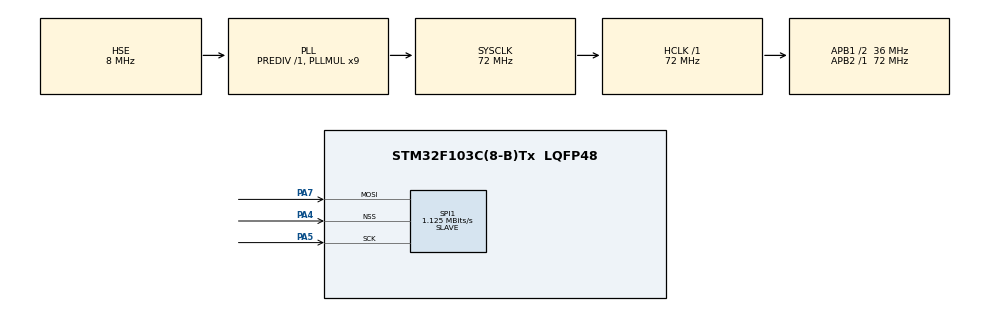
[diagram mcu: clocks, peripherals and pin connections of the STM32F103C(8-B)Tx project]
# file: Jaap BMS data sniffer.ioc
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Dma.Request0=SPI1_RX
Dma.SPI1_RX.0.Direction=DMA_PERIPH_TO_MEMORY
Dma.SPI1_RX.0.Instance=DMA1_Channel2
Dma.SPI1_RX.0.MemDataAlignment=DMA_MDATAALIGN_BYTE
Dma.SPI1_RX.0.MemInc=DMA_MINC_ENABLE
Dma.SPI1_RX.0.Mode=DMA_CIRCULAR
Dma.SPI1_RX.0.PeriphDataAlignment=DMA_PDATAALIGN_BYTE
Dma.SPI1_RX.0.PeriphInc=DMA_PINC_DISABLE
Dma.SPI1_RX.0.Priority=DMA_PRIORITY_LOW
Mcu.Family=STM32F1
Mcu.Name=STM32F103C(8-B)Tx
Mcu.Package=LQFP48
NVIC.PriorityGroup=NVIC_PRIORITYGROUP_4
PA13.Mode=Serial_Wire
PA13.Signal=SYS_JTMS-SWDIO
PA14.Mode=Serial_Wire
PA14.Signal=SYS_JTCK-SWCLK
PA4.Mode=NSS_Signal_Hard_Input
PA4.Signal=SPI1_NSS
PA5.Mode=RX_Only_Simplex_Unidirect_Slave
PA5.Signal=SPI1_SCK
PA7.Mode=RX_Only_Simplex_Unidirect_Slave
PA7.Signal=SPI1_MOSI
PD0-OSC_IN.Mode=HSE-External-Oscillator
PD0-OSC_IN.Signal=RCC_OSC_IN
PD1-OSC_OUT.Mode=HSE-External-Oscillator
PD1-OSC_OUT.Signal=RCC_OSC_OUT
ProjectManager.HeapSize=0x200
ProjectManager.StackSize=0x400
ProjectManager.TargetToolchain=STM32CubeIDE
RCC.AHBFreq_Value=72000000
RCC.APB1CLKDivider=RCC_HCLK_DIV2
RCC.APB1Freq_Value=36000000
RCC.APB1TimFreq_Value=72000000
RCC.APB2Freq_Value=72000000
RCC.APB2TimFreq_Value=72000000
RCC.HCLKFreq_Value=72000000
RCC.PLLMUL=RCC_PLL_MUL9
RCC.PLLSourceVirtual=RCC_PLLSOURCE_HSE
RCC.SYSCLKFreq_VALUE=72000000
RCC.SYSCLKSource=RCC_SYSCLKSOURCE_PLLCLK
RCC.USBFreq_Value=72000000
SPI1.BaudRatePrescaler=SPI_BAUDRATEPRESCALER_64
SPI1.CalculateBaudRate=1.125 MBits/s
SPI1.Direction=SPI_DIRECTION_2LINES_RXONLY
SPI1.Mode=SPI_MODE_SLAVE
SPI1.VirtualNSS=VM_NSSHARD
SPI1.VirtualType=VM_SLAVE
board=custom

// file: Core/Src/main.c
/* USER CODE BEGIN Header */
/**
 ******************************************************************************
 * @file           : main.c
 * @brief          : Main program body
 ******************************************************************************
 * @attention
 *
 * <h2><center>&copy; Copyright (c) 2021 STMicroelectronics.
 * All rights reserved.</center></h2>
 *
 * This software component is licensed by ST under BSD 3-Clause license,
 * the "License"; You may not use this file except in compliance with the
 * License. You may obtain a copy of the License at:
 *                        opensource.org/licenses/BSD-3-Clause
 *
 ******************************************************************************
 */
/* USER CODE END Header */
#include "main.h"
#include "dma.h"
#include "spi.h"
#include "gpio.h"

/* USER CODE BEGIN Includes */
#include "stm32f1xx_it.h"

/* USER CODE END Includes */

/* USER CODE BEGIN PV */

// Size for circular SPI Data buffer
#define SPI_DATA_SIZE 500

// Actual buffer
uint8_t SPI_Data[SPI_DATA_SIZE];

// Index in the DMA SPI Data array
uint32_t DMA_Index;

// RAM to store NRF Data packet into
uint8_t SPI_Data_Packet[32];

// Variables to store
float current, voltage, ah, kwh;

/* USER CODE END PV */

void SystemClock_Config(void);

int main(void)
{

	/* MCU Configuration--------------------------------------------------------*/

	/* Reset of all peripherals, Initializes the Flash interface and the Systick. */
	HAL_Init();

	/* Configure the system clock */
	SystemClock_Config();

	/* Initialize all configured peripherals */
	MX_GPIO_Init();
	MX_DMA_Init();
	MX_SPI1_Init();
	/* USER CODE BEGIN 2 */

	// Enable DMA from SPI
	HAL_SPI_Receive_DMA(&hspi1, SPI_Data, SPI_DATA_SIZE);

	// Turn off HAL Systick - gives interrupts every ms. Might fuck up HAL functions that use timeouts
	HAL_SuspendTick();

	/* USER CODE END 2 */

	/* Infinite loop */
	/* USER CODE BEGIN WHILE */
	while (1) {

		// If the current DMA data index is different than the last one we saved we got new data
		if (SPI_DATA_SIZE - hspi1.hdmarx->Instance->CNDTR != DMA_Index){

			// Save the new index
			DMA_Index = SPI_DATA_SIZE - hspi1.hdmarx->Instance->CNDTR;

			// Calculate the possible start index of a NRF Data packet
			uint32_t startIndex = (DMA_Index + SPI_DATA_SIZE - 32) % SPI_DATA_SIZE;

			// If we actually found the data we'd expect in there we found a valid packet
			if (SPI_Data[startIndex] == 0xA0 && SPI_Data[(startIndex + 1) % SPI_DATA_SIZE] == 0x36){

				// Save the values to a new array for easier processing
				for (int i = 0; i < 32; i++){
					SPI_Data_Packet[i] = SPI_Data[(startIndex + i + 1) % SPI_DATA_SIZE];
				}

				// Calculate the values
				current = (SPI_Data_Packet[1] * 256 + SPI_Data_Packet[2]) / 100.0f;
				voltage = (SPI_Data_Packet[3] * 256 + SPI_Data_Packet[4]) / 100.0f;
				ah =      (SPI_Data_Packet[7] * 256 + SPI_Data_Packet[8]) / 1000.0f;
				kwh =     (SPI_Data_Packet[11] * 256 + SPI_Data_Packet[12]) / 1000.0f;
			}
		}

		/* USER CODE END WHILE */

	}
}

void SystemClock_Config(void)
{
	RCC_OscInitTypeDef RCC_OscInitStruct = {0};
	RCC_ClkInitTypeDef RCC_ClkInitStruct = {0};

	/** Initializes the RCC Oscillators according to the specified parameters
	 * in the RCC_OscInitTypeDef structure.
	 */
	RCC_OscInitStruct.OscillatorType = RCC_OSCILLATORTYPE_HSE;
	RCC_OscInitStruct.HSEState = RCC_HSE_ON;
	RCC_OscInitStruct.HSEPredivValue = RCC_HSE_PREDIV_DIV1;
	RCC_OscInitStruct.HSIState = RCC_HSI_ON;
	RCC_OscInitStruct.PLL.PLLState = RCC_PLL_ON;
	RCC_OscInitStruct.PLL.PLLSource = RCC_PLLSOURCE_HSE;
	RCC_OscInitStruct.PLL.PLLMUL = RCC_PLL_MUL9;
	if (HAL_RCC_OscConfig(&RCC_OscInitStruct) != HAL_OK)
	{
		Error_Handler();
	}
	/** Initializes the CPU, AHB and APB buses clocks
	 */
	RCC_ClkInitStruct.ClockType = RCC_CLOCKTYPE_HCLK|RCC_CLOCKTYPE_SYSCLK
			|RCC_CLOCKTYPE_PCLK1|RCC_CLOCKTYPE_PCLK2;
	RCC_ClkInitStruct.SYSCLKSource = RCC_SYSCLKSOURCE_PLLCLK;
	RCC_ClkInitStruct.AHBCLKDivider = RCC_SYSCLK_DIV1;
	RCC_ClkInitStruct.APB1CLKDivider = RCC_HCLK_DIV2;
	RCC_ClkInitStruct.APB2CLKDivider = RCC_HCLK_DIV1;

	if (HAL_RCC_ClockConfig(&RCC_ClkInitStruct, FLASH_LATENCY_2) != HAL_OK)
	{
		Error_Handler();
	}
}

void Error_Handler(void)
{
	__disable_irq();
	while (1)
	{
	}
}

/************************ (C) COPYRIGHT STMicroelectronics *****END OF FILE****/
